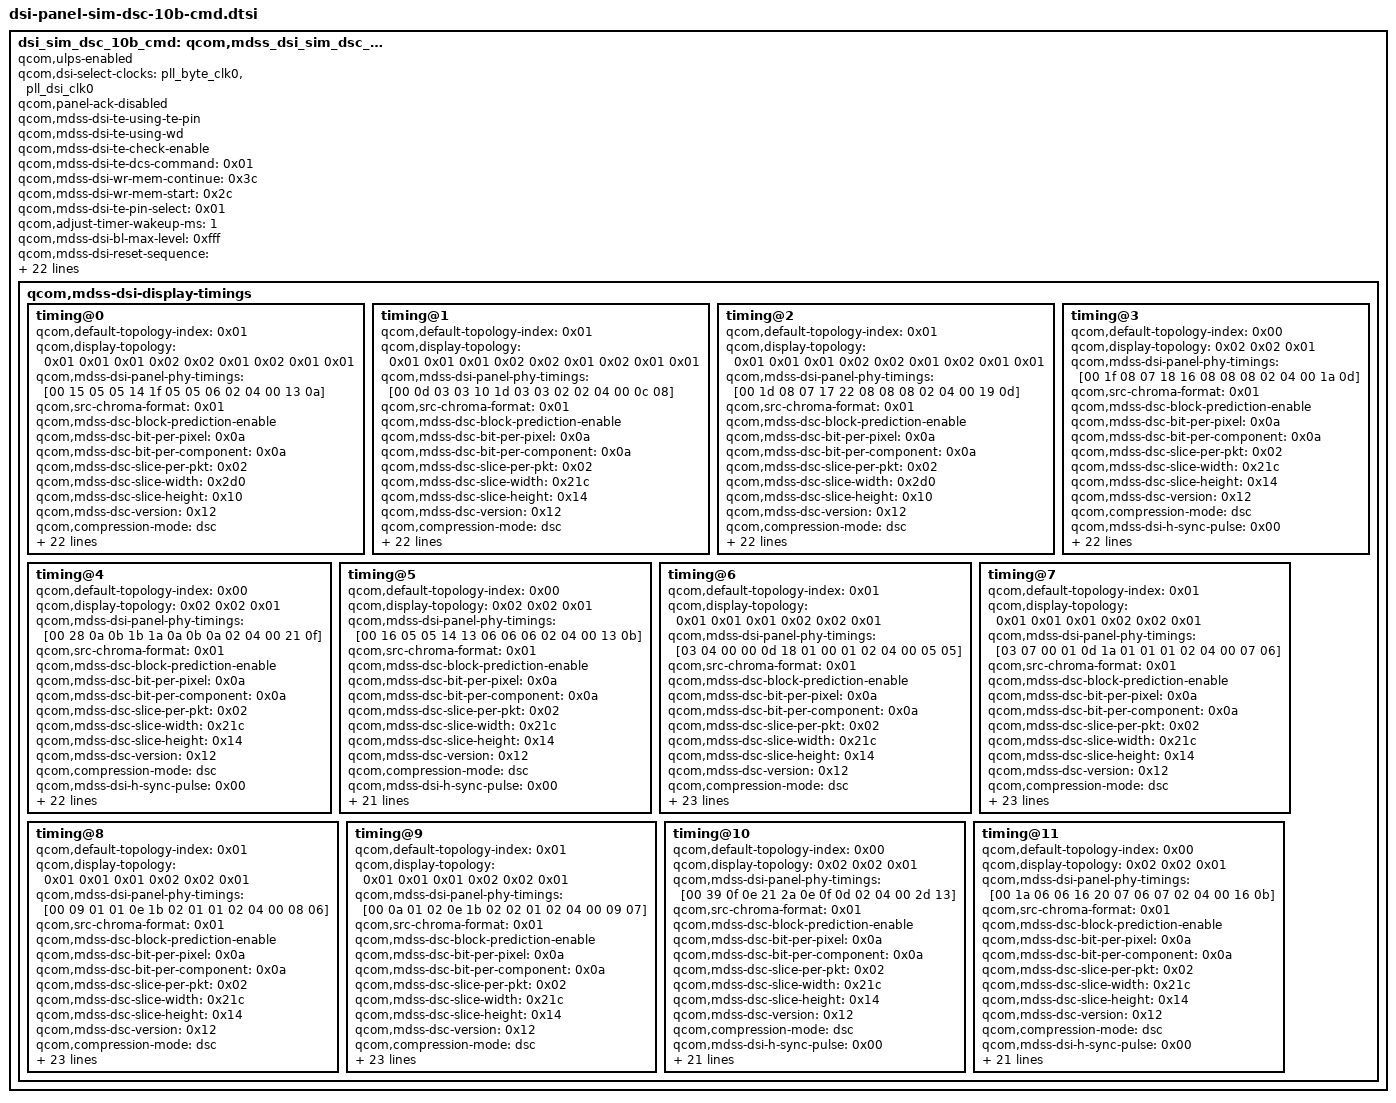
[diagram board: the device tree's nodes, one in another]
// SPDX-License-Identifier: BSD-3-Clause
/*
 * Copyright (c) 2023-2024 Qualcomm Innovation Center, Inc. All rights reserved.
 * Copyright (c) 2025 The LineageOS Project
 */

dsi_sim_dsc_10b_cmd: qcom,mdss_dsi_sim_dsc_10b_cmd {
	qcom,ulps-enabled;
	qcom,dsi-select-clocks = "pll_byte_clk0", "pll_dsi_clk0";
	qcom,panel-ack-disabled;
	qcom,mdss-dsi-te-using-te-pin;
	qcom,mdss-dsi-te-using-wd;
	qcom,mdss-dsi-te-check-enable;
	qcom,mdss-dsi-te-dcs-command = <0x01>;
	qcom,mdss-dsi-wr-mem-continue = <0x3c>;
	qcom,mdss-dsi-wr-mem-start = <0x2c>;
	qcom,mdss-dsi-te-pin-select = <0x01>;
	qcom,adjust-timer-wakeup-ms = <1>;
	qcom,mdss-dsi-bl-max-level = <0xfff>;
	qcom,mdss-dsi-reset-sequence = <0x01 0x0a 0x00 0x0a 0x01 0x0a>;
	qcom,mdss-dsi-mdp-trigger = "none";
	qcom,mdss-dsi-dma-trigger = "trigger_sw";
	qcom,mdss-dsi-lane-3-state;
	qcom,mdss-dsi-lane-2-state;
	qcom,mdss-dsi-lane-1-state;
	qcom,mdss-dsi-lane-0-state;
	qcom,mdss-dsi-bllp-power-mode;
	qcom,mdss-dsi-bllp-eof-power-mode;
	qcom,mdss-dsi-traffic-mode = "non_burst_sync_event";
	qcom,mdss-dsi-border-color = <0x00>;
	qcom,mdss-dsi-underflow-color = <0xff>;
	qcom,mdss-dsi-color-order = "rgb_swap_rgb";
	qcom,mdss-dsi-bpp = <0x1e>;
	qcom,mdss-dsi-stream = <0x00>;
	qcom,mdss-dsi-virtual-channel-id = <0x00>;
	qcom,dsi-phy-num = <0x00>;
	qcom,dsi-ctrl-num = <0x00>;
	qcom,mdss-dsi-panel-type = "dsi_cmd_mode";
	qcom,mdss-dsi-panel-name = "Simulator cmd mode DSC3:1 10bit dsi panel";

	qcom,mdss-dsi-display-timings {

		timing@0 {
			qcom,default-topology-index = <0x01>;
			qcom,display-topology = <0x01 0x01 0x01 0x02 0x02 0x01 0x02 0x01 0x01>;
			qcom,mdss-dsi-panel-phy-timings = [00 15 05 05 14 1f 05 05 06 02 04 00 13 0a];
			qcom,src-chroma-format = <0x01>;
			qcom,mdss-dsc-block-prediction-enable;
			qcom,mdss-dsc-bit-per-pixel = <0x0a>;
			qcom,mdss-dsc-bit-per-component = <0x0a>;
			qcom,mdss-dsc-slice-per-pkt = <0x02>;
			qcom,mdss-dsc-slice-width = <0x2d0>;
			qcom,mdss-dsc-slice-height = <0x10>;
			qcom,mdss-dsc-version = <0x12>;
			qcom,compression-mode = "dsc";
			qcom,mdss-dsi-h-sync-pulse = <0x00>;
			qcom,mdss-dsi-off-command-state = "dsi_hs_mode";
			qcom,mdss-dsi-on-command-state = "dsi_hs_mode";
			qcom,mdss-dsi-off-command = [05 01 00 00 78 00 02 28 00 05 01 00 00 78 00 02 10 00];
			qcom,mdss-dsi-on-command = [15 01 00 00 00 00 02 ff 20 15 01 00 00 00 00 02 fb 01 15 01 00 00 00 00 02 00 01 15 01 00 00 00 00 02 01 55 15 01 00 00 00 00 02 02 45 15 01 00 00 00 00 02 05 40 15 01 00 00 00 00 02 06 19 15 01 00 00 00 00 02 07 1e 15 01 00 00 00 00 02 0b 73 15 01 00 00 00 00 02 0c 73 15 01 00 00 00 00 02 0e b0 15 01 00 00 00 00 02 0f ae 15 01 00 00 00 00 02 11 b8 15 01 00 00 00 00 02 13 00 15 01 00 00 00 00 02 58 80 15 01 00 00 00 00 02 59 01 15 01 00 00 00 00 02 5a 00 15 01 00 00 00 00 02 5b 01 15 01 00 00 00 00 02 5c 80 15 01 00 00 00 00 02 5d 81 15 01 00 00 00 00 02 5e 00 15 01 00 00 00 00 02 5f 01 15 01 00 00 00 00 02 72 31 15 01 00 00 00 00 02 68 03 15 01 00 00 00 00 02 ff 24 15 01 00 00 00 00 02 fb 01 15 01 00 00 00 00 02 00 1c 15 01 00 00 00 00 02 01 0b 15 01 00 00 00 00 02 02 0c 15 01 00 00 00 00 02 03 01 15 01 00 00 00 00 02 04 0f 15 01 00 00 00 00 02 05 10 15 01 00 00 00 00 02 06 10 15 01 00 00 00 00 02 07 10 15 01 00 00 00 00 02 08 89 15 01 00 00 00 00 02 09 8a 15 01 00 00 00 00 02 0a 13 15 01 00 00 00 00 02 0b 13 15 01 00 00 00 00 02 0c 15 15 01 00 00 00 00 02 0d 15 15 01 00 00 00 00 02 0e 17 15 01 00 00 00 00 02 0f 17 15 01 00 00 00 00 02 10 1c 15 01 00 00 00 00 02 11 0b 15 01 00 00 00 00 02 12 0c 15 01 00 00 00 00 02 13 01 15 01 00 00 00 00 02 14 0f 15 01 00 00 00 00 02 15 10 15 01 00 00 00 00 02 16 10 15 01 00 00 00 00 02 17 10 15 01 00 00 00 00 02 18 89 15 01 00 00 00 00 02 19 8a 15 01 00 00 00 00 02 1a 13 15 01 00 00 00 00 02 1b 13 15 01 00 00 00 00 02 1c 15 15 01 00 00 00 00 02 1d 15 15 01 00 00 00 00 02 1e 17 15 01 00 00 00 00 02 1f 17 15 01 00 00 00 00 02 20 40 15 01 00 00 00 00 02 21 01 15 01 00 00 00 00 02 22 00 15 01 00 00 00 00 02 23 40 15 01 00 00 00 00 02 24 40 15 01 00 00 00 00 02 25 6d 15 01 00 00 00 00 02 26 40 15 01 00 00 00 00 02 27 40 15 01 00 00 00 00 02 e0 00 15 01 00 00 00 00 02 dc 21 15 01 00 00 00 00 02 dd 22 15 01 00 00 00 00 02 de 07 15 01 00 00 00 00 02 df 07 15 01 00 00 00 00 02 e3 6d 15 01 00 00 00 00 02 e1 07 15 01 00 00 00 00 02 e2 07 15 01 00 00 00 00 02 29 d8 15 01 00 00 00 00 02 2a 2a 15 01 00 00 00 00 02 4b 03 15 01 00 00 00 00 02 4c 11 15 01 00 00 00 00 02 4d 10 15 01 00 00 00 00 02 4e 01 15 01 00 00 00 00 02 4f 01 15 01 00 00 00 00 02 50 10 15 01 00 00 00 00 02 51 00 15 01 00 00 00 00 02 52 80 15 01 00 00 00 00 02 53 00 15 01 00 00 00 00 02 56 00 15 01 00 00 00 00 02 54 07 15 01 00 00 00 00 02 58 07 15 01 00 00 00 00 02 55 25 15 01 00 00 00 00 02 5b 43 15 01 00 00 00 00 02 5c 00 15 01 00 00 00 00 02 5f 73 15 01 00 00 00 00 02 60 73 15 01 00 00 00 00 02 63 22 15 01 00 00 00 00 02 64 00 15 01 00 00 00 00 02 67 08 15 01 00 00 00 00 02 68 04 15 01 00 00 00 00 02 72 02 15 01 00 00 00 00 02 7a 80 15 01 00 00 00 00 02 7b 91 15 01 00 00 00 00 02 7c d8 15 01 00 00 00 00 02 7d 60 15 01 00 00 00 00 02 7f 15 15 01 00 00 00 00 02 75 15 15 01 00 00 00 00 02 b3 c0 15 01 00 00 00 00 02 b4 00 15 01 00 00 00 00 02 b5 00 15 01 00 00 00 00 02 78 00 15 01 00 00 00 00 02 79 00 15 01 00 00 00 00 02 80 00 15 01 00 00 00 00 02 83 00 15 01 00 00 00 00 02 93 0a 15 01 00 00 00 00 02 94 0a 15 01 00 00 00 00 02 8a 00 15 01 00 00 00 00 02 9b ff 15 01 00 00 00 00 02 9d b0 15 01 00 00 00 00 02 9f 63 15 01 00 00 00 00 02 98 10 15 01 00 00 00 00 02 ec 00 15 01 00 00 00 00 02 ff 10 39 01 00 00 00 00 11 c1 09 20 00 10 02 00 02 68 01 bb 00 0a 06 67 04 c5 39 01 00 00 00 00 03 c2 10 f0 15 01 00 00 00 00 02 c0 03 39 01 00 00 00 00 04 3b 03 0a 0a 15 01 00 00 00 00 02 35 00 15 01 00 00 00 00 02 e5 01 15 01 00 00 00 00 02 bb 10 15 01 00 00 00 00 02 fb 01 05 01 00 00 f0 00 01 00];
			qcom,mdss-dsi-v-bottom-border = <0x00>;
			qcom,mdss-dsi-v-top-border = <0x00>;
			qcom,mdss-dsi-h-right-border = <0x00>;
			qcom,mdss-dsi-h-left-border = <0x00>;
			qcom,mdss-dsi-v-pulse-width = <0x02>;
			qcom,mdss-dsi-v-front-porch = <0x0a>;
			qcom,mdss-dsi-v-back-porch = <0x08>;
			qcom,mdss-dsi-h-sync-skew = <0x00>;
			qcom,mdss-dsi-h-pulse-width = <0x10>;
			qcom,mdss-dsi-h-back-porch = <0x20>;
			qcom,mdss-dsi-h-front-porch = <0x64>;
			qcom,mdss-dsi-panel-height = <0xa00>;
			qcom,mdss-dsi-panel-width = <0x5a0>;
			qcom,mdss-dsi-panel-framerate = <0x3c>;
			cell-index = <0x00>;
		};

		timing@1 {
			qcom,default-topology-index = <0x01>;
			qcom,display-topology = <0x01 0x01 0x01 0x02 0x02 0x01 0x02 0x01 0x01>;
			qcom,mdss-dsi-panel-phy-timings = [00 0d 03 03 10 1d 03 03 02 02 04 00 0c 08];
			qcom,src-chroma-format = <0x01>;
			qcom,mdss-dsc-block-prediction-enable;
			qcom,mdss-dsc-bit-per-pixel = <0x0a>;
			qcom,mdss-dsc-bit-per-component = <0x0a>;
			qcom,mdss-dsc-slice-per-pkt = <0x02>;
			qcom,mdss-dsc-slice-width = <0x21c>;
			qcom,mdss-dsc-slice-height = <0x14>;
			qcom,mdss-dsc-version = <0x12>;
			qcom,compression-mode = "dsc";
			qcom,mdss-dsi-h-sync-pulse = <0x00>;
			qcom,mdss-dsi-off-command-state = "dsi_hs_mode";
			qcom,mdss-dsi-on-command-state = "dsi_lp_mode";
			qcom,mdss-dsi-off-command = <0x5010000 0x10000128 0x5010000 0x40000110>;
			qcom,mdss-dsi-on-command = <0x15010000 0x2bb 0x10150100 0x02 0xb0030501 0x7800 0x1111501 0x00 0x251ff15 0x1000000 0x25324 0x15010000 0x2ff 0x23150100 0x02 0x8051501 0x00 0x2469015 0x1000000 0x2ff10 0x15010000 0x2ff 0xf0150100 0x02 0x92011501 0x00 0x2ff1015 0x1000000 0x23500 0x5010000 0x28000129 0x5010000 0xf0000100>;
			qcom,mdss-dsi-panel-framerate = <0x3c>;
			qcom,mdss-dsi-v-bottom-border = <0x00>;
			qcom,mdss-dsi-v-top-border = <0x00>;
			qcom,mdss-dsi-h-right-border = <0x00>;
			qcom,mdss-dsi-h-left-border = <0x00>;
			qcom,mdss-dsi-v-pulse-width = <0x00>;
			qcom,mdss-dsi-v-front-porch = <0x00>;
			qcom,mdss-dsi-v-back-porch = <0x00>;
			qcom,mdss-dsi-h-sync-skew = <0x00>;
			qcom,mdss-dsi-h-pulse-width = <0x00>;
			qcom,mdss-dsi-h-back-porch = <0x00>;
			qcom,mdss-dsi-h-front-porch = <0x00>;
			qcom,mdss-dsi-panel-height = <0x924>;
			qcom,mdss-dsi-panel-width = <0x438>;
			cell-index = <0x01>;
		};

		timing@2 {
			qcom,default-topology-index = <0x01>;
			qcom,display-topology = <0x01 0x01 0x01 0x02 0x02 0x01 0x02 0x01 0x01>;
			qcom,mdss-dsi-panel-phy-timings = [00 1d 08 07 17 22 08 08 08 02 04 00 19 0d];
			qcom,src-chroma-format = <0x01>;
			qcom,mdss-dsc-block-prediction-enable;
			qcom,mdss-dsc-bit-per-pixel = <0x0a>;
			qcom,mdss-dsc-bit-per-component = <0x0a>;
			qcom,mdss-dsc-slice-per-pkt = <0x02>;
			qcom,mdss-dsc-slice-width = <0x2d0>;
			qcom,mdss-dsc-slice-height = <0x10>;
			qcom,mdss-dsc-version = <0x12>;
			qcom,compression-mode = "dsc";
			qcom,mdss-dsi-h-sync-pulse = <0x00>;
			qcom,mdss-dsi-off-command-state = "dsi_hs_mode";
			qcom,mdss-dsi-on-command-state = "dsi_hs_mode";
			qcom,mdss-dsi-off-command = [05 01 00 00 78 00 02 28 00 05 01 00 00 78 00 02 10 00];
			qcom,mdss-dsi-on-command = [15 01 00 00 00 00 02 ff 20 15 01 00 00 00 00 02 fb 01 15 01 00 00 00 00 02 00 01 15 01 00 00 00 00 02 01 55 15 01 00 00 00 00 02 02 45 15 01 00 00 00 00 02 05 40 15 01 00 00 00 00 02 06 19 15 01 00 00 00 00 02 07 1e 15 01 00 00 00 00 02 0b 73 15 01 00 00 00 00 02 0c 73 15 01 00 00 00 00 02 0e b0 15 01 00 00 00 00 02 0f ae 15 01 00 00 00 00 02 11 b8 15 01 00 00 00 00 02 13 00 15 01 00 00 00 00 02 58 80 15 01 00 00 00 00 02 59 01 15 01 00 00 00 00 02 5a 00 15 01 00 00 00 00 02 5b 01 15 01 00 00 00 00 02 5c 80 15 01 00 00 00 00 02 5d 81 15 01 00 00 00 00 02 5e 00 15 01 00 00 00 00 02 5f 01 15 01 00 00 00 00 02 72 31 15 01 00 00 00 00 02 68 03 15 01 00 00 00 00 02 ff 24 15 01 00 00 00 00 02 fb 01 15 01 00 00 00 00 02 00 1c 15 01 00 00 00 00 02 01 0b 15 01 00 00 00 00 02 02 0c 15 01 00 00 00 00 02 03 01 15 01 00 00 00 00 02 04 0f 15 01 00 00 00 00 02 05 10 15 01 00 00 00 00 02 06 10 15 01 00 00 00 00 02 07 10 15 01 00 00 00 00 02 08 89 15 01 00 00 00 00 02 09 8a 15 01 00 00 00 00 02 0a 13 15 01 00 00 00 00 02 0b 13 15 01 00 00 00 00 02 0c 15 15 01 00 00 00 00 02 0d 15 15 01 00 00 00 00 02 0e 17 15 01 00 00 00 00 02 0f 17 15 01 00 00 00 00 02 10 1c 15 01 00 00 00 00 02 11 0b 15 01 00 00 00 00 02 12 0c 15 01 00 00 00 00 02 13 01 15 01 00 00 00 00 02 14 0f 15 01 00 00 00 00 02 15 10 15 01 00 00 00 00 02 16 10 15 01 00 00 00 00 02 17 10 15 01 00 00 00 00 02 18 89 15 01 00 00 00 00 02 19 8a 15 01 00 00 00 00 02 1a 13 15 01 00 00 00 00 02 1b 13 15 01 00 00 00 00 02 1c 15 15 01 00 00 00 00 02 1d 15 15 01 00 00 00 00 02 1e 17 15 01 00 00 00 00 02 1f 17 15 01 00 00 00 00 02 20 40 15 01 00 00 00 00 02 21 01 15 01 00 00 00 00 02 22 00 15 01 00 00 00 00 02 23 40 15 01 00 00 00 00 02 24 40 15 01 00 00 00 00 02 25 6d 15 01 00 00 00 00 02 26 40 15 01 00 00 00 00 02 27 40 15 01 00 00 00 00 02 e0 00 15 01 00 00 00 00 02 dc 21 15 01 00 00 00 00 02 dd 22 15 01 00 00 00 00 02 de 07 15 01 00 00 00 00 02 df 07 15 01 00 00 00 00 02 e3 6d 15 01 00 00 00 00 02 e1 07 15 01 00 00 00 00 02 e2 07 15 01 00 00 00 00 02 29 d8 15 01 00 00 00 00 02 2a 2a 15 01 00 00 00 00 02 4b 03 15 01 00 00 00 00 02 4c 11 15 01 00 00 00 00 02 4d 10 15 01 00 00 00 00 02 4e 01 15 01 00 00 00 00 02 4f 01 15 01 00 00 00 00 02 50 10 15 01 00 00 00 00 02 51 00 15 01 00 00 00 00 02 52 80 15 01 00 00 00 00 02 53 00 15 01 00 00 00 00 02 56 00 15 01 00 00 00 00 02 54 07 15 01 00 00 00 00 02 58 07 15 01 00 00 00 00 02 55 25 15 01 00 00 00 00 02 5b 43 15 01 00 00 00 00 02 5c 00 15 01 00 00 00 00 02 5f 73 15 01 00 00 00 00 02 60 73 15 01 00 00 00 00 02 63 22 15 01 00 00 00 00 02 64 00 15 01 00 00 00 00 02 67 08 15 01 00 00 00 00 02 68 04 15 01 00 00 00 00 02 72 02 15 01 00 00 00 00 02 7a 80 15 01 00 00 00 00 02 7b 91 15 01 00 00 00 00 02 7c d8 15 01 00 00 00 00 02 7d 60 15 01 00 00 00 00 02 7f 15 15 01 00 00 00 00 02 75 15 15 01 00 00 00 00 02 b3 c0 15 01 00 00 00 00 02 b4 00 15 01 00 00 00 00 02 b5 00 15 01 00 00 00 00 02 78 00 15 01 00 00 00 00 02 79 00 15 01 00 00 00 00 02 80 00 15 01 00 00 00 00 02 83 00 15 01 00 00 00 00 02 93 0a 15 01 00 00 00 00 02 94 0a 15 01 00 00 00 00 02 8a 00 15 01 00 00 00 00 02 9b ff 15 01 00 00 00 00 02 9d b0 15 01 00 00 00 00 02 9f 63 15 01 00 00 00 00 02 98 10 15 01 00 00 00 00 02 ec 00 15 01 00 00 00 00 02 ff 10 39 01 00 00 00 00 11 c1 09 20 00 10 02 00 02 68 01 bb 00 0a 06 67 04 c5 39 01 00 00 00 00 03 c2 10 f0 15 01 00 00 00 00 02 c0 03 39 01 00 00 00 00 04 3b 03 0a 0a 15 01 00 00 00 00 02 35 00 15 01 00 00 00 00 02 e5 01 15 01 00 00 00 00 02 bb 10 15 01 00 00 00 00 02 fb 01 05 01 00 00 f0 00 01 00];
			qcom,mdss-dsi-v-bottom-border = <0x00>;
			qcom,mdss-dsi-v-top-border = <0x00>;
			qcom,mdss-dsi-h-right-border = <0x00>;
			qcom,mdss-dsi-h-left-border = <0x00>;
			qcom,mdss-dsi-v-pulse-width = <0x02>;
			qcom,mdss-dsi-v-front-porch = <0x0a>;
			qcom,mdss-dsi-v-back-porch = <0x08>;
			qcom,mdss-dsi-h-sync-skew = <0x00>;
			qcom,mdss-dsi-h-pulse-width = <0x10>;
			qcom,mdss-dsi-h-back-porch = <0x20>;
			qcom,mdss-dsi-h-front-porch = <0x64>;
			qcom,mdss-dsi-panel-height = <0xa00>;
			qcom,mdss-dsi-panel-width = <0x5a0>;
			qcom,mdss-dsi-panel-framerate = <0x5a>;
			cell-index = <0x02>;
		};

		timing@3 {
			qcom,default-topology-index = <0x00>;
			qcom,display-topology = <0x02 0x02 0x01>;
			qcom,mdss-dsi-panel-phy-timings = [00 1f 08 07 18 16 08 08 08 02 04 00 1a 0d];
			qcom,src-chroma-format = <0x01>;
			qcom,mdss-dsc-block-prediction-enable;
			qcom,mdss-dsc-bit-per-pixel = <0x0a>;
			qcom,mdss-dsc-bit-per-component = <0x0a>;
			qcom,mdss-dsc-slice-per-pkt = <0x02>;
			qcom,mdss-dsc-slice-width = <0x21c>;
			qcom,mdss-dsc-slice-height = <0x14>;
			qcom,mdss-dsc-version = <0x12>;
			qcom,compression-mode = "dsc";
			qcom,mdss-dsi-h-sync-pulse = <0x00>;
			qcom,mdss-dsi-off-command-state = "dsi_hs_mode";
			qcom,mdss-dsi-on-command-state = "dsi_hs_mode";
			qcom,mdss-dsi-off-command = [05 01 00 00 78 00 02 28 00 05 01 00 00 78 00 02 10 00];
			qcom,mdss-dsi-on-command = [15 01 00 00 00 00 02 ff 20 15 01 00 00 00 00 02 fb 01 15 01 00 00 00 00 02 00 01 15 01 00 00 00 00 02 01 55 15 01 00 00 00 00 02 02 45 15 01 00 00 00 00 02 05 40 15 01 00 00 00 00 02 06 19 15 01 00 00 00 00 02 07 1e 15 01 00 00 00 00 02 0b 73 15 01 00 00 00 00 02 0c 73 15 01 00 00 00 00 02 0e b0 15 01 00 00 00 00 02 0f ae 15 01 00 00 00 00 02 11 b8 15 01 00 00 00 00 02 13 00 15 01 00 00 00 00 02 58 80 15 01 00 00 00 00 02 59 01 15 01 00 00 00 00 02 5a 00 15 01 00 00 00 00 02 5b 01 15 01 00 00 00 00 02 5c 80 15 01 00 00 00 00 02 5d 81 15 01 00 00 00 00 02 5e 00 15 01 00 00 00 00 02 5f 01 15 01 00 00 00 00 02 72 31 15 01 00 00 00 00 02 68 03 15 01 00 00 00 00 02 ff 24 15 01 00 00 00 00 02 fb 01 15 01 00 00 00 00 02 00 1c 15 01 00 00 00 00 02 01 0b 15 01 00 00 00 00 02 02 0c 15 01 00 00 00 00 02 03 01 15 01 00 00 00 00 02 04 0f 15 01 00 00 00 00 02 05 10 15 01 00 00 00 00 02 06 10 15 01 00 00 00 00 02 07 10 15 01 00 00 00 00 02 08 89 15 01 00 00 00 00 02 09 8a 15 01 00 00 00 00 02 0a 13 15 01 00 00 00 00 02 0b 13 15 01 00 00 00 00 02 0c 15 15 01 00 00 00 00 02 0d 15 15 01 00 00 00 00 02 0e 17 15 01 00 00 00 00 02 0f 17 15 01 00 00 00 00 02 10 1c 15 01 00 00 00 00 02 11 0b 15 01 00 00 00 00 02 12 0c 15 01 00 00 00 00 02 13 01 15 01 00 00 00 00 02 14 0f 15 01 00 00 00 00 02 15 10 15 01 00 00 00 00 02 16 10 15 01 00 00 00 00 02 17 10 15 01 00 00 00 00 02 18 89 15 01 00 00 00 00 02 19 8a 15 01 00 00 00 00 02 1a 13 15 01 00 00 00 00 02 1b 13 15 01 00 00 00 00 02 1c 15 15 01 00 00 00 00 02 1d 15 15 01 00 00 00 00 02 1e 17 15 01 00 00 00 00 02 1f 17 15 01 00 00 00 00 02 20 40 15 01 00 00 00 00 02 21 01 15 01 00 00 00 00 02 22 00 15 01 00 00 00 00 02 23 40 15 01 00 00 00 00 02 24 40 15 01 00 00 00 00 02 25 6d 15 01 00 00 00 00 02 26 40 15 01 00 00 00 00 02 27 40 15 01 00 00 00 00 02 e0 00 15 01 00 00 00 00 02 dc 21 15 01 00 00 00 00 02 dd 22 15 01 00 00 00 00 02 de 07 15 01 00 00 00 00 02 df 07 15 01 00 00 00 00 02 e3 6d 15 01 00 00 00 00 02 e1 07 15 01 00 00 00 00 02 e2 07 15 01 00 00 00 00 02 29 d8 15 01 00 00 00 00 02 2a 2a 15 01 00 00 00 00 02 4b 03 15 01 00 00 00 00 02 4c 11 15 01 00 00 00 00 02 4d 10 15 01 00 00 00 00 02 4e 01 15 01 00 00 00 00 02 4f 01 15 01 00 00 00 00 02 50 10 15 01 00 00 00 00 02 51 00 15 01 00 00 00 00 02 52 80 15 01 00 00 00 00 02 53 00 15 01 00 00 00 00 02 56 00 15 01 00 00 00 00 02 54 07 15 01 00 00 00 00 02 58 07 15 01 00 00 00 00 02 55 25 15 01 00 00 00 00 02 5b 43 15 01 00 00 00 00 02 5c 00 15 01 00 00 00 00 02 5f 73 15 01 00 00 00 00 02 60 73 15 01 00 00 00 00 02 63 22 15 01 00 00 00 00 02 64 00 15 01 00 00 00 00 02 67 08 15 01 00 00 00 00 02 68 04 15 01 00 00 00 00 02 72 02 15 01 00 00 00 00 02 7a 80 15 01 00 00 00 00 02 7b 91 15 01 00 00 00 00 02 7c d8 15 01 00 00 00 00 02 7d 60 15 01 00 00 00 00 02 7f 15 15 01 00 00 00 00 02 75 15 15 01 00 00 00 00 02 b3 c0 15 01 00 00 00 00 02 b4 00 15 01 00 00 00 00 02 b5 00 15 01 00 00 00 00 02 78 00 15 01 00 00 00 00 02 79 00 15 01 00 00 00 00 02 80 00 15 01 00 00 00 00 02 83 00 15 01 00 00 00 00 02 93 0a 15 01 00 00 00 00 02 94 0a 15 01 00 00 00 00 02 8a 00 15 01 00 00 00 00 02 9b ff 15 01 00 00 00 00 02 9d b0 15 01 00 00 00 00 02 9f 63 15 01 00 00 00 00 02 98 10 15 01 00 00 00 00 02 ec 00 15 01 00 00 00 00 02 ff 10 39 01 00 00 00 00 11 c1 09 20 00 10 02 00 02 68 01 bb 00 0a 06 67 04 c5 39 01 00 00 00 00 03 c2 10 f0 15 01 00 00 00 00 02 c0 03 39 01 00 00 00 00 04 3b 03 0a 0a 15 01 00 00 00 00 02 35 00 15 01 00 00 00 00 02 e5 01 15 01 00 00 00 00 02 bb 10 15 01 00 00 00 00 02 fb 01];
			qcom,disable-rsc-solver;
			qcom,mdss-dsi-v-bottom-border = <0x00>;
			qcom,mdss-dsi-v-top-border = <0x00>;
			qcom,mdss-dsi-h-right-border = <0x00>;
			qcom,mdss-dsi-h-left-border = <0x00>;
			qcom,mdss-dsi-v-pulse-width = <0x02>;
			qcom,mdss-dsi-v-front-porch = <0x0a>;
			qcom,mdss-dsi-v-back-porch = <0x08>;
			qcom,mdss-dsi-h-sync-skew = <0x00>;
			qcom,mdss-dsi-h-pulse-width = <0x10>;
			qcom,mdss-dsi-h-back-porch = <0x20>;
			qcom,mdss-dsi-h-front-porch = <0x64>;
			qcom,mdss-dsi-panel-height = <0x924>;
			qcom,mdss-dsi-panel-width = <0x438>;
			qcom,mdss-dsi-panel-framerate = <0xb4>;
			cell-index = <0x03>;
		};

		timing@4 {
			qcom,default-topology-index = <0x00>;
			qcom,display-topology = <0x02 0x02 0x01>;
			qcom,mdss-dsi-panel-phy-timings = [00 28 0a 0b 1b 1a 0a 0b 0a 02 04 00 21 0f];
			qcom,src-chroma-format = <0x01>;
			qcom,mdss-dsc-block-prediction-enable;
			qcom,mdss-dsc-bit-per-pixel = <0x0a>;
			qcom,mdss-dsc-bit-per-component = <0x0a>;
			qcom,mdss-dsc-slice-per-pkt = <0x02>;
			qcom,mdss-dsc-slice-width = <0x21c>;
			qcom,mdss-dsc-slice-height = <0x14>;
			qcom,mdss-dsc-version = <0x12>;
			qcom,compression-mode = "dsc";
			qcom,mdss-dsi-h-sync-pulse = <0x00>;
			qcom,mdss-dsi-off-command-state = "dsi_hs_mode";
			qcom,mdss-dsi-on-command-state = "dsi_hs_mode";
			qcom,mdss-dsi-off-command = [05 01 00 00 78 00 02 28 00 05 01 00 00 78 00 02 10 00];
			qcom,mdss-dsi-on-command = [15 01 00 00 00 00 02 ff 20 15 01 00 00 00 00 02 fb 01 15 01 00 00 00 00 02 00 01 15 01 00 00 00 00 02 01 55 15 01 00 00 00 00 02 02 45 15 01 00 00 00 00 02 05 40 15 01 00 00 00 00 02 06 19 15 01 00 00 00 00 02 07 1e 15 01 00 00 00 00 02 0b 73 15 01 00 00 00 00 02 0c 73 15 01 00 00 00 00 02 0e b0 15 01 00 00 00 00 02 0f ae 15 01 00 00 00 00 02 11 b8 15 01 00 00 00 00 02 13 00 15 01 00 00 00 00 02 58 80 15 01 00 00 00 00 02 59 01 15 01 00 00 00 00 02 5a 00 15 01 00 00 00 00 02 5b 01 15 01 00 00 00 00 02 5c 80 15 01 00 00 00 00 02 5d 81 15 01 00 00 00 00 02 5e 00 15 01 00 00 00 00 02 5f 01 15 01 00 00 00 00 02 72 31 15 01 00 00 00 00 02 68 03 15 01 00 00 00 00 02 ff 24 15 01 00 00 00 00 02 fb 01 15 01 00 00 00 00 02 00 1c 15 01 00 00 00 00 02 01 0b 15 01 00 00 00 00 02 02 0c 15 01 00 00 00 00 02 03 01 15 01 00 00 00 00 02 04 0f 15 01 00 00 00 00 02 05 10 15 01 00 00 00 00 02 06 10 15 01 00 00 00 00 02 07 10 15 01 00 00 00 00 02 08 89 15 01 00 00 00 00 02 09 8a 15 01 00 00 00 00 02 0a 13 15 01 00 00 00 00 02 0b 13 15 01 00 00 00 00 02 0c 15 15 01 00 00 00 00 02 0d 15 15 01 00 00 00 00 02 0e 17 15 01 00 00 00 00 02 0f 17 15 01 00 00 00 00 02 10 1c 15 01 00 00 00 00 02 11 0b 15 01 00 00 00 00 02 12 0c 15 01 00 00 00 00 02 13 01 15 01 00 00 00 00 02 14 0f 15 01 00 00 00 00 02 15 10 15 01 00 00 00 00 02 16 10 15 01 00 00 00 00 02 17 10 15 01 00 00 00 00 02 18 89 15 01 00 00 00 00 02 19 8a 15 01 00 00 00 00 02 1a 13 15 01 00 00 00 00 02 1b 13 15 01 00 00 00 00 02 1c 15 15 01 00 00 00 00 02 1d 15 15 01 00 00 00 00 02 1e 17 15 01 00 00 00 00 02 1f 17 15 01 00 00 00 00 02 20 40 15 01 00 00 00 00 02 21 01 15 01 00 00 00 00 02 22 00 15 01 00 00 00 00 02 23 40 15 01 00 00 00 00 02 24 40 15 01 00 00 00 00 02 25 6d 15 01 00 00 00 00 02 26 40 15 01 00 00 00 00 02 27 40 15 01 00 00 00 00 02 e0 00 15 01 00 00 00 00 02 dc 21 15 01 00 00 00 00 02 dd 22 15 01 00 00 00 00 02 de 07 15 01 00 00 00 00 02 df 07 15 01 00 00 00 00 02 e3 6d 15 01 00 00 00 00 02 e1 07 15 01 00 00 00 00 02 e2 07 15 01 00 00 00 00 02 29 d8 15 01 00 00 00 00 02 2a 2a 15 01 00 00 00 00 02 4b 03 15 01 00 00 00 00 02 4c 11 15 01 00 00 00 00 02 4d 10 15 01 00 00 00 00 02 4e 01 15 01 00 00 00 00 02 4f 01 15 01 00 00 00 00 02 50 10 15 01 00 00 00 00 02 51 00 15 01 00 00 00 00 02 52 80 15 01 00 00 00 00 02 53 00 15 01 00 00 00 00 02 56 00 15 01 00 00 00 00 02 54 07 15 01 00 00 00 00 02 58 07 15 01 00 00 00 00 02 55 25 15 01 00 00 00 00 02 5b 43 15 01 00 00 00 00 02 5c 00 15 01 00 00 00 00 02 5f 73 15 01 00 00 00 00 02 60 73 15 01 00 00 00 00 02 63 22 15 01 00 00 00 00 02 64 00 15 01 00 00 00 00 02 67 08 15 01 00 00 00 00 02 68 04 15 01 00 00 00 00 02 72 02 15 01 00 00 00 00 02 7a 80 15 01 00 00 00 00 02 7b 91 15 01 00 00 00 00 02 7c d8 15 01 00 00 00 00 02 7d 60 15 01 00 00 00 00 02 7f 15 15 01 00 00 00 00 02 75 15 15 01 00 00 00 00 02 b3 c0 15 01 00 00 00 00 02 b4 00 15 01 00 00 00 00 02 b5 00 15 01 00 00 00 00 02 78 00 15 01 00 00 00 00 02 79 00 15 01 00 00 00 00 02 80 00 15 01 00 00 00 00 02 83 00 15 01 00 00 00 00 02 93 0a 15 01 00 00 00 00 02 94 0a 15 01 00 00 00 00 02 8a 00 15 01 00 00 00 00 02 9b ff 15 01 00 00 00 00 02 9d b0 15 01 00 00 00 00 02 9f 63 15 01 00 00 00 00 02 98 10 15 01 00 00 00 00 02 ec 00 15 01 00 00 00 00 02 ff 10 39 01 00 00 00 00 11 c1 09 20 00 10 02 00 02 68 01 bb 00 0a 06 67 04 c5 39 01 00 00 00 00 03 c2 10 f0 15 01 00 00 00 00 02 c0 03 39 01 00 00 00 00 04 3b 03 0a 0a 15 01 00 00 00 00 02 35 00 15 01 00 00 00 00 02 e5 01 15 01 00 00 00 00 02 bb 10 15 01 00 00 00 00 02 fb 01];
			qcom,disable-rsc-solver;
			qcom,mdss-dsi-v-bottom-border = <0x00>;
			qcom,mdss-dsi-v-top-border = <0x00>;
			qcom,mdss-dsi-h-right-border = <0x00>;
			qcom,mdss-dsi-h-left-border = <0x00>;
			qcom,mdss-dsi-v-pulse-width = <0x02>;
			qcom,mdss-dsi-v-front-porch = <0x0a>;
			qcom,mdss-dsi-v-back-porch = <0x08>;
			qcom,mdss-dsi-h-sync-skew = <0x00>;
			qcom,mdss-dsi-h-pulse-width = <0x10>;
			qcom,mdss-dsi-h-back-porch = <0x20>;
			qcom,mdss-dsi-h-front-porch = <0x64>;
			qcom,mdss-dsi-panel-height = <0x924>;
			qcom,mdss-dsi-panel-width = <0x438>;
			qcom,mdss-dsi-panel-framerate = <0xf0>;
			cell-index = <0x04>;
		};

		timing@5 {
			qcom,default-topology-index = <0x00>;
			qcom,display-topology = <0x02 0x02 0x01>;
			qcom,mdss-dsi-panel-phy-timings = [00 16 05 05 14 13 06 06 06 02 04 00 13 0b];
			qcom,src-chroma-format = <0x01>;
			qcom,mdss-dsc-block-prediction-enable;
			qcom,mdss-dsc-bit-per-pixel = <0x0a>;
			qcom,mdss-dsc-bit-per-component = <0x0a>;
			qcom,mdss-dsc-slice-per-pkt = <0x02>;
			qcom,mdss-dsc-slice-width = <0x21c>;
			qcom,mdss-dsc-slice-height = <0x14>;
			qcom,mdss-dsc-version = <0x12>;
			qcom,compression-mode = "dsc";
			qcom,mdss-dsi-h-sync-pulse = <0x00>;
			qcom,mdss-dsi-off-command-state = "dsi_hs_mode";
			qcom,mdss-dsi-on-command-state = "dsi_lp_mode";
			qcom,mdss-dsi-off-command = <0x5010000 0x10000128 0x5010000 0x40000110>;
			qcom,mdss-dsi-on-command = <0x15010000 0x2bb 0x10150100 0x02 0xb0030501 0x7800 0x1111501 0x00 0x251ff15 0x1000000 0x25324 0x15010000 0x2ff 0x23150100 0x02 0x8051501 0x00 0x2469015 0x1000000 0x2ff10 0x15010000 0x2ff 0xf0150100 0x02 0x92011501 0x00 0x2ff1015 0x1000000 0x23500 0x5010000 0x28000129>;
			qcom,mdss-dsi-panel-framerate = <0x78>;
			qcom,mdss-dsi-v-bottom-border = <0x00>;
			qcom,mdss-dsi-v-top-border = <0x00>;
			qcom,mdss-dsi-h-right-border = <0x00>;
			qcom,mdss-dsi-h-left-border = <0x00>;
			qcom,mdss-dsi-v-pulse-width = <0x00>;
			qcom,mdss-dsi-v-front-porch = <0x00>;
			qcom,mdss-dsi-v-back-porch = <0x00>;
			qcom,mdss-dsi-h-sync-skew = <0x00>;
			qcom,mdss-dsi-h-pulse-width = <0x00>;
			qcom,mdss-dsi-h-back-porch = <0x00>;
			qcom,mdss-dsi-h-front-porch = <0x00>;
			qcom,mdss-dsi-panel-height = <0x924>;
			qcom,mdss-dsi-panel-width = <0x438>;
			cell-index = <0x05>;
		};

		timing@6 {
			qcom,default-topology-index = <0x01>;
			qcom,display-topology = <0x01 0x01 0x01 0x02 0x02 0x01>;
			qcom,mdss-dsi-panel-phy-timings = [03 04 00 00 0d 18 01 00 01 02 04 00 05 05];
			qcom,src-chroma-format = <0x01>;
			qcom,mdss-dsc-block-prediction-enable;
			qcom,mdss-dsc-bit-per-pixel = <0x0a>;
			qcom,mdss-dsc-bit-per-component = <0x0a>;
			qcom,mdss-dsc-slice-per-pkt = <0x02>;
			qcom,mdss-dsc-slice-width = <0x21c>;
			qcom,mdss-dsc-slice-height = <0x14>;
			qcom,mdss-dsc-version = <0x12>;
			qcom,compression-mode = "dsc";
			qcom,mdss-dsi-h-sync-pulse = <0x00>;
			qcom,mdss-dsi-off-command-state = "dsi_hs_mode";
			qcom,mdss-dsi-on-command-state = "dsi_lp_mode";
			qcom,mdss-dsi-off-command = <0x5010000 0x10000128 0x5010000 0x40000110>;
			qcom,mdss-dsi-on-command = <0x15010000 0x2bb 0x10150100 0x02 0xb0030501 0x7800 0x1111501 0x00 0x251ff15 0x1000000 0x25324 0x15010000 0x2ff 0x23150100 0x02 0x8051501 0x00 0x2469015 0x1000000 0x2ff10 0x15010000 0x2ff 0xf0150100 0x02 0x92011501 0x00 0x2ff1015 0x1000000 0x23500 0x5010000 0x28000129>;
			qcom,mdss-mdp-transfer-time-us = <15652>;
			qcom,mdss-dsi-panel-framerate = <0x01>;
			qcom,mdss-dsi-v-bottom-border = <0x00>;
			qcom,mdss-dsi-v-top-border = <0x00>;
			qcom,mdss-dsi-h-right-border = <0x00>;
			qcom,mdss-dsi-h-left-border = <0x00>;
			qcom,mdss-dsi-v-pulse-width = <0x00>;
			qcom,mdss-dsi-v-front-porch = <0x00>;
			qcom,mdss-dsi-v-back-porch = <0x00>;
			qcom,mdss-dsi-h-sync-skew = <0x00>;
			qcom,mdss-dsi-h-pulse-width = <0x00>;
			qcom,mdss-dsi-h-back-porch = <0x00>;
			qcom,mdss-dsi-h-front-porch = <0x00>;
			qcom,mdss-dsi-panel-height = <0x924>;
			qcom,mdss-dsi-panel-width = <0x438>;
			cell-index = <0x06>;
		};

		timing@7 {
			qcom,default-topology-index = <0x01>;
			qcom,display-topology = <0x01 0x01 0x01 0x02 0x02 0x01>;
			qcom,mdss-dsi-panel-phy-timings = [03 07 00 01 0d 1a 01 01 01 02 04 00 07 06];
			qcom,src-chroma-format = <0x01>;
			qcom,mdss-dsc-block-prediction-enable;
			qcom,mdss-dsc-bit-per-pixel = <0x0a>;
			qcom,mdss-dsc-bit-per-component = <0x0a>;
			qcom,mdss-dsc-slice-per-pkt = <0x02>;
			qcom,mdss-dsc-slice-width = <0x21c>;
			qcom,mdss-dsc-slice-height = <0x14>;
			qcom,mdss-dsc-version = <0x12>;
			qcom,compression-mode = "dsc";
			qcom,mdss-dsi-h-sync-pulse = <0x00>;
			qcom,mdss-dsi-off-command-state = "dsi_hs_mode";
			qcom,mdss-dsi-on-command-state = "dsi_lp_mode";
			qcom,mdss-dsi-off-command = <0x5010000 0x10000128 0x5010000 0x40000110>;
			qcom,mdss-dsi-on-command = <0x15010000 0x2bb 0x10150100 0x02 0xb0030501 0x7800 0x1111501 0x00 0x251ff15 0x1000000 0x25324 0x15010000 0x2ff 0x23150100 0x02 0x8051501 0x00 0x2469015 0x1000000 0x2ff10 0x15010000 0x2ff 0xf0150100 0x02 0x92011501 0x00 0x2ff1015 0x1000000 0x23500 0x5010000 0x28000129>;
			qcom,mdss-mdp-transfer-time-us = <15652>;
			qcom,mdss-dsi-panel-framerate = <0x0a>;
			qcom,mdss-dsi-v-bottom-border = <0x00>;
			qcom,mdss-dsi-v-top-border = <0x00>;
			qcom,mdss-dsi-h-right-border = <0x00>;
			qcom,mdss-dsi-h-left-border = <0x00>;
			qcom,mdss-dsi-v-pulse-width = <0x00>;
			qcom,mdss-dsi-v-front-porch = <0x00>;
			qcom,mdss-dsi-v-back-porch = <0x00>;
			qcom,mdss-dsi-h-sync-skew = <0x00>;
			qcom,mdss-dsi-h-pulse-width = <0x00>;
			qcom,mdss-dsi-h-back-porch = <0x00>;
			qcom,mdss-dsi-h-front-porch = <0x00>;
			qcom,mdss-dsi-panel-height = <0x924>;
			qcom,mdss-dsi-panel-width = <0x438>;
			cell-index = <0x07>;
		};

		timing@8 {
			qcom,default-topology-index = <0x01>;
			qcom,display-topology = <0x01 0x01 0x01 0x02 0x02 0x01>;
			qcom,mdss-dsi-panel-phy-timings = [00 09 01 01 0e 1b 02 01 01 02 04 00 08 06];
			qcom,src-chroma-format = <0x01>;
			qcom,mdss-dsc-block-prediction-enable;
			qcom,mdss-dsc-bit-per-pixel = <0x0a>;
			qcom,mdss-dsc-bit-per-component = <0x0a>;
			qcom,mdss-dsc-slice-per-pkt = <0x02>;
			qcom,mdss-dsc-slice-width = <0x21c>;
			qcom,mdss-dsc-slice-height = <0x14>;
			qcom,mdss-dsc-version = <0x12>;
			qcom,compression-mode = "dsc";
			qcom,mdss-dsi-h-sync-pulse = <0x00>;
			qcom,mdss-dsi-off-command-state = "dsi_hs_mode";
			qcom,mdss-dsi-on-command-state = "dsi_lp_mode";
			qcom,mdss-dsi-off-command = <0x5010000 0x10000128 0x5010000 0x40000110>;
			qcom,mdss-dsi-on-command = <0x15010000 0x2bb 0x10150100 0x02 0xb0030501 0x7800 0x1111501 0x00 0x251ff15 0x1000000 0x25324 0x15010000 0x2ff 0x23150100 0x02 0x8051501 0x00 0x2469015 0x1000000 0x2ff10 0x15010000 0x2ff 0xf0150100 0x02 0x92011501 0x00 0x2ff1015 0x1000000 0x23500 0x5010000 0x28000129>;
			qcom,mdss-mdp-transfer-time-us = <15652>;
			qcom,mdss-dsi-panel-framerate = <0x18>;
			qcom,mdss-dsi-v-bottom-border = <0x00>;
			qcom,mdss-dsi-v-top-border = <0x00>;
			qcom,mdss-dsi-h-right-border = <0x00>;
			qcom,mdss-dsi-h-left-border = <0x00>;
			qcom,mdss-dsi-v-pulse-width = <0x00>;
			qcom,mdss-dsi-v-front-porch = <0x00>;
			qcom,mdss-dsi-v-back-porch = <0x00>;
			qcom,mdss-dsi-h-sync-skew = <0x00>;
			qcom,mdss-dsi-h-pulse-width = <0x00>;
			qcom,mdss-dsi-h-back-porch = <0x00>;
			qcom,mdss-dsi-h-front-porch = <0x00>;
			qcom,mdss-dsi-panel-height = <0x924>;
			qcom,mdss-dsi-panel-width = <0x438>;
			cell-index = <0x08>;
		};

		timing@9 {
			qcom,default-topology-index = <0x01>;
			qcom,display-topology = <0x01 0x01 0x01 0x02 0x02 0x01>;
			qcom,mdss-dsi-panel-phy-timings = [00 0a 01 02 0e 1b 02 02 01 02 04 00 09 07];
			qcom,src-chroma-format = <0x01>;
			qcom,mdss-dsc-block-prediction-enable;
			qcom,mdss-dsc-bit-per-pixel = <0x0a>;
			qcom,mdss-dsc-bit-per-component = <0x0a>;
			qcom,mdss-dsc-slice-per-pkt = <0x02>;
			qcom,mdss-dsc-slice-width = <0x21c>;
			qcom,mdss-dsc-slice-height = <0x14>;
			qcom,mdss-dsc-version = <0x12>;
			qcom,compression-mode = "dsc";
			qcom,mdss-dsi-h-sync-pulse = <0x00>;
			qcom,mdss-dsi-off-command-state = "dsi_hs_mode";
			qcom,mdss-dsi-on-command-state = "dsi_lp_mode";
			qcom,mdss-dsi-off-command = <0x5010000 0x10000128 0x5010000 0x40000110>;
			qcom,mdss-dsi-on-command = <0x15010000 0x2bb 0x10150100 0x02 0xb0030501 0x7800 0x1111501 0x00 0x251ff15 0x1000000 0x25324 0x15010000 0x2ff 0x23150100 0x02 0x8051501 0x00 0x2469015 0x1000000 0x2ff10 0x15010000 0x2ff 0xf0150100 0x02 0x92011501 0x00 0x2ff1015 0x1000000 0x23500 0x5010000 0x28000129>;
			qcom,mdss-mdp-transfer-time-us = <15652>;
			qcom,mdss-dsi-panel-framerate = <0x1e>;
			qcom,mdss-dsi-v-bottom-border = <0x00>;
			qcom,mdss-dsi-v-top-border = <0x00>;
			qcom,mdss-dsi-h-right-border = <0x00>;
			qcom,mdss-dsi-h-left-border = <0x00>;
			qcom,mdss-dsi-v-pulse-width = <0x00>;
			qcom,mdss-dsi-v-front-porch = <0x00>;
			qcom,mdss-dsi-v-back-porch = <0x00>;
			qcom,mdss-dsi-h-sync-skew = <0x00>;
			qcom,mdss-dsi-h-pulse-width = <0x00>;
			qcom,mdss-dsi-h-back-porch = <0x00>;
			qcom,mdss-dsi-h-front-porch = <0x00>;
			qcom,mdss-dsi-panel-height = <0x924>;
			qcom,mdss-dsi-panel-width = <0x438>;
			cell-index = <0x09>;
		};

		timing@10 {
			qcom,default-topology-index = <0x00>;
			qcom,display-topology = <0x02 0x02 0x01>;
			qcom,mdss-dsi-panel-phy-timings = [00 39 0f 0e 21 2a 0e 0f 0d 02 04 00 2d 13];
			qcom,src-chroma-format = <0x01>;
			qcom,mdss-dsc-block-prediction-enable;
			qcom,mdss-dsc-bit-per-pixel = <0x0a>;
			qcom,mdss-dsc-bit-per-component = <0x0a>;
			qcom,mdss-dsc-slice-per-pkt = <0x02>;
			qcom,mdss-dsc-slice-width = <0x21c>;
			qcom,mdss-dsc-slice-height = <0x14>;
			qcom,mdss-dsc-version = <0x12>;
			qcom,compression-mode = "dsc";
			qcom,mdss-dsi-h-sync-pulse = <0x00>;
			qcom,mdss-dsi-off-command-state = "dsi_hs_mode";
			qcom,mdss-dsi-on-command-state = "dsi_lp_mode";
			qcom,mdss-dsi-off-command = <0x5010000 0x10000128 0x5010000 0x40000110>;
			qcom,mdss-dsi-on-command = <0x15010000 0x2bb 0x10150100 0x02 0xb0030501 0x7800 0x1111501 0x00 0x251ff15 0x1000000 0x25324 0x15010000 0x2ff 0x23150100 0x02 0x8051501 0x00 0x2469015 0x1000000 0x2ff10 0x15010000 0x2ff 0xf0150100 0x02 0x92011501 0x00 0x2ff1015 0x1000000 0x23500 0x5010000 0x28000129>;
			qcom,mdss-dsi-panel-framerate = <0x5a>;
			qcom,mdss-dsi-v-bottom-border = <0x00>;
			qcom,mdss-dsi-v-top-border = <0x00>;
			qcom,mdss-dsi-h-right-border = <0x00>;
			qcom,mdss-dsi-h-left-border = <0x00>;
			qcom,mdss-dsi-v-pulse-width = <0x00>;
			qcom,mdss-dsi-v-front-porch = <0x00>;
			qcom,mdss-dsi-v-back-porch = <0x00>;
			qcom,mdss-dsi-h-sync-skew = <0x00>;
			qcom,mdss-dsi-h-pulse-width = <0x00>;
			qcom,mdss-dsi-h-back-porch = <0x00>;
			qcom,mdss-dsi-h-front-porch = <0x00>;
			qcom,mdss-dsi-panel-height = <0x924>;
			qcom,mdss-dsi-panel-width = <0x438>;
			cell-index = <0x0a>;
		};

		timing@11 {
			qcom,default-topology-index = <0x00>;
			qcom,display-topology = <0x02 0x02 0x01>;
			qcom,mdss-dsi-panel-phy-timings = [00 1a 06 06 16 20 07 06 07 02 04 00 16 0b];
			qcom,src-chroma-format = <0x01>;
			qcom,mdss-dsc-block-prediction-enable;
			qcom,mdss-dsc-bit-per-pixel = <0x0a>;
			qcom,mdss-dsc-bit-per-component = <0x0a>;
			qcom,mdss-dsc-slice-per-pkt = <0x02>;
			qcom,mdss-dsc-slice-width = <0x21c>;
			qcom,mdss-dsc-slice-height = <0x14>;
			qcom,mdss-dsc-version = <0x12>;
			qcom,compression-mode = "dsc";
			qcom,mdss-dsi-h-sync-pulse = <0x00>;
			qcom,mdss-dsi-off-command-state = "dsi_hs_mode";
			qcom,mdss-dsi-on-command-state = "dsi_lp_mode";
			qcom,mdss-dsi-off-command = <0x5010000 0x10000128 0x5010000 0x40000110>;
			qcom,mdss-dsi-on-command = <0x15010000 0x2bb 0x10150100 0x02 0xb0030501 0x7800 0x1111501 0x00 0x251ff15 0x1000000 0x25324 0x15010000 0x2ff 0x23150100 0x02 0x8051501 0x00 0x2469015 0x1000000 0x2ff10 0x15010000 0x2ff 0xf0150100 0x02 0x92011501 0x00 0x2ff1015 0x1000000 0x23500 0x5010000 0x28000129>;
			qcom,mdss-dsi-panel-framerate = <0x90>;
			qcom,mdss-dsi-v-bottom-border = <0x00>;
			qcom,mdss-dsi-v-top-border = <0x00>;
			qcom,mdss-dsi-h-right-border = <0x00>;
			qcom,mdss-dsi-h-left-border = <0x00>;
			qcom,mdss-dsi-v-pulse-width = <0x00>;
			qcom,mdss-dsi-v-front-porch = <0x00>;
			qcom,mdss-dsi-v-back-porch = <0x00>;
			qcom,mdss-dsi-h-sync-skew = <0x00>;
			qcom,mdss-dsi-h-pulse-width = <0x00>;
			qcom,mdss-dsi-h-back-porch = <0x00>;
			qcom,mdss-dsi-h-front-porch = <0x00>;
			qcom,mdss-dsi-panel-height = <0x924>;
			qcom,mdss-dsi-panel-width = <0x438>;
			cell-index = <0x0b>;
		};
	};
};
